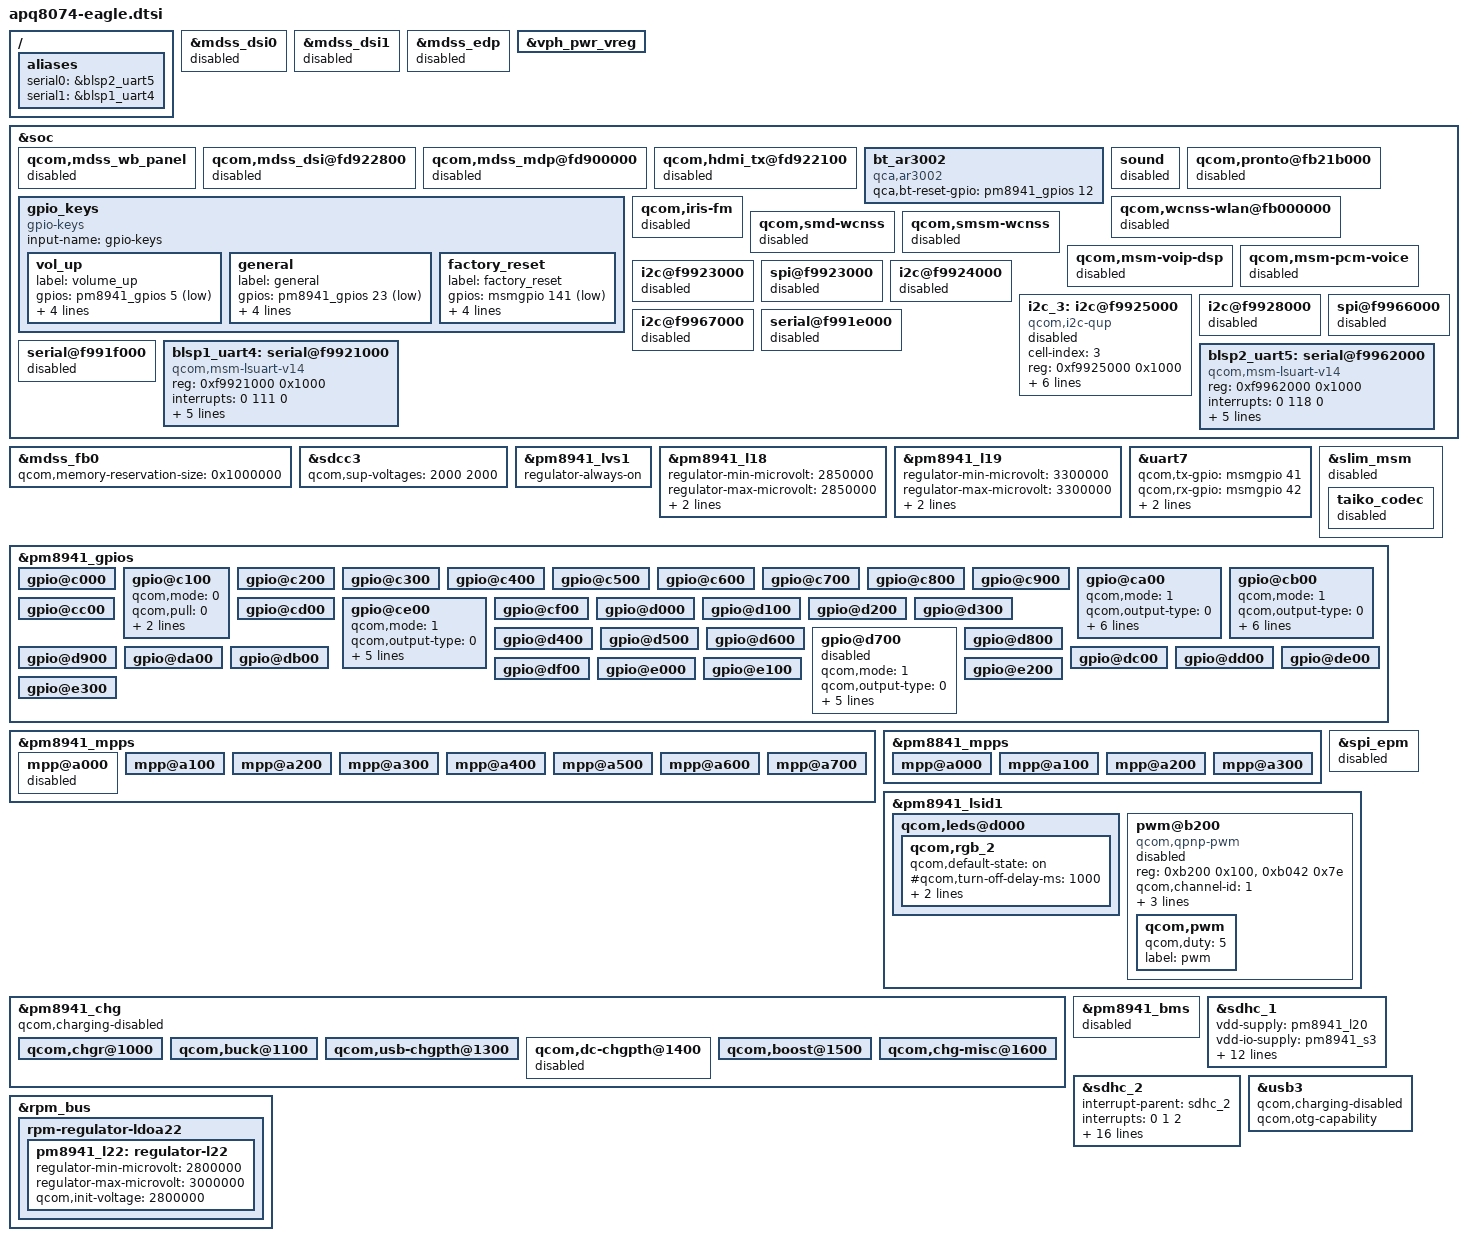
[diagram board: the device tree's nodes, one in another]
/* Copyright (c) 2013-2015, The Linux Foundation. All rights reserved.
 *
 * This program is free software; you can redistribute it and/or modify
 * it under the terms of the GNU General Public License version 2 and
 * only version 2 as published by the Free Software Foundation.
 *
 * This program is distributed in the hope that it will be useful,
 * but WITHOUT ANY WARRANTY; without even the implied warranty of
 * MERCHANTABILITY or FITNESS FOR A PARTICULAR PURPOSE.  See the
 * GNU General Public License for more details.
 */

/include/ "apq8074-camera-sensor-eagle.dtsi"
/include/ "msm8974-leds.dtsi"
/include/ "msm-rdbg.dtsi"
/include/ "apq8074-leds-eagle.dtsi"

/ {
	aliases {
		serial0 = &blsp2_uart5;
        serial1 = &blsp1_uart4;
	};
};

&mdss_dsi0 {
    status = "disabled";
};

&mdss_dsi1 {
    status = "disabled";
};

&mdss_edp {
    status = "disabled";
};

&vph_pwr_vreg {
	status = "ok";
};

&soc {

    qcom,mdss_wb_panel {
		status = "disabled";
	};

	qcom,mdss_dsi@fd922800 {
		status = "disabled";
	};

	qcom,mdss_mdp@fd900000 {
		status = "disabled";
	};

	qcom,hdmi_tx@fd922100 {
		status = "disabled";
	};

	gpio_keys {
		compatible = "gpio-keys";
		input-name = "gpio-keys";

		vol_up {
			label = "volume_up";
			gpios = <&pm8941_gpios 5 0x1>;
			linux,input-type = <1>;
			linux,code = <115>;
			gpio-key,wakeup;
			debounce-interval = <15>;
		};

		general {
			label = "general";
			gpios = <&pm8941_gpios 23 0x1>;
			linux,input-type = <1>;
			linux,code = <102>;
			gpio-key,wakeup;
			debounce-interval = <15>;
		};

		factory_reset {
			label = "factory_reset";
			gpios = <&msmgpio 141 0x1>;
			linux,input-type = <1>;
			linux,code = <766>;
			gpio-key,wakeup;
			debounce-interval = <15>;
		};
	};

	bt_ar3002 {
		compatible = "qca,ar3002";
		qca,bt-reset-gpio = <&pm8941_gpios 12 0>;
	};

	sound {
        status = "disabled";        
	};

	qcom,pronto@fb21b000 {
		status = "disabled";
	};

	qcom,iris-fm {
		status = "disabled";
	};

	qcom,wcnss-wlan@fb000000 {
		status = "disabled";
	};

	qcom,smd-wcnss {
		status = "disabled";
	};

	qcom,smsm-wcnss {
		status = "disabled";
	};

	qcom,msm-voip-dsp {
		status = "disabled";
	};

	qcom,msm-pcm-voice {
		status = "disabled";
	};


    /* blsp1 - qup i2c - na */
	i2c@f9923000 {
		status = "disabled";
	};

    /* blsp1 - qup spi - na */
	spi@f9923000 {
		status = "disabled";
	};

    /* blsp2 - qup i2c - na */
	i2c@f9924000 {
		status = "disabled";
	};

	/* blsp2 - qup i2c - barometer (keep disabled) */
	i2c_3: i2c@f9925000 {
		cell-index = <3>;
		compatible = "qcom,i2c-qup";
		reg = <0xf9925000 0x1000>;
		#address-cells = <1>;
		#size-cells = <0>;
		reg-names = "qup_phys_addr";
		interrupts = <0 97 0>;
		interrupt-names = "qup_err_intr";
		qcom,i2c-bus-freq = <384000>;
		qcom,i2c-src-freq = <19200000>;
		qcom,master-id = <86>;
		qcom,scl-gpio = <&msmgpio 11 0>;
		qcom,sda-gpio = <&msmgpio 10 0>;
		status = "disabled";
	};

    /* blsp6 - qup i2c - na */
	i2c@f9928000 {
		status = "disabled";
	};

	/* msm8974.dtsi */
    /* blsp10 - qup spi - na */
	spi@f9966000 {
		status = "disabled";
	};

	/* msm8974.dtsi */
    /* blsp11 - qup i2c - na */
	i2c@f9967000 {
		status = "disabled";
	};

	/* msm8974.dtsi */
    /* blsp2 - uart - na */
	serial@f991e000 {
		status = "disabled";
	};

	/* msm8974.dtsi */
    /* blsp3 - uart - na */
	serial@f991f000 {
		status = "disabled";
	};

	/* Not defined */
    /* blsp5 - uart - GPS */
	blsp1_uart4: serial@f9921000 {
		compatible = "qcom,msm-lsuart-v14";
		reg = <0xf9921000 0x1000>;
		interrupts = <0 111 0>;
		status = "okay";

		qcom,msm-bus,name = "serial_uart5";
		qcom,msm-bus,num-cases = <2>;
		qcom,msm-bus,num-paths = <1>;
		qcom,msm-bus,vectors-KBps =
				<86 512 0 0>,
				<86 512 500 800>;
	};

    /* blsp12 - serial console */
	blsp2_uart5: serial@f9962000 {
		compatible = "qcom,msm-lsuart-v14";
		reg = <0xf9962000 0x1000>;
		interrupts = <0 118 0>;
		status = "okay";

		qcom,msm-bus,name = "serial_uart12";
		qcom,msm-bus,num-cases = <2>;
		qcom,msm-bus,num-paths = <1>;
		qcom,msm-bus,vectors-KBps =
				<84 512 0 0>,
				<84 512 500 800>;
	};
};

&mdss_fb0 {
	qcom,memory-reservation-size = <0x1000000>; /* size 16MB */
};

&sdcc3 {
	qcom,sup-voltages = <2000 2000>;
	status = "ok";
};

&pm8941_lvs1 {
	regulator-always-on;
};

&pm8941_l18 {
    regulator-min-microvolt = <2850000>;
    regulator-max-microvolt = <2850000>;
    qcom,init-voltage = <2850000>;
	regulator-always-on;
};


&pm8941_l19 {
	regulator-min-microvolt = <3300000>;
	regulator-max-microvolt = <3300000>;
	qcom,init-voltage = <3300000>;
	regulator-always-on;
};

/* blsp7 - bt uart */
&uart7 {
	status = "ok";
	qcom,tx-gpio = <&msmgpio 41 0x00>;
	qcom,rx-gpio = <&msmgpio 42 0x00>;
	qcom,cts-gpio = <&msmgpio 43 0x00>;
	qcom,rfr-gpio = <&msmgpio 44 0x00>;
};

&slim_msm {
	status = "disabled";
	taiko_codec {
		status = "disabled";
	};
};

&pm8941_gpios {
	gpio@c000 { /* GPIO 1 */
	};

	gpio@c100 { /* GPIO 2 */
		qcom,mode = <0>;
		qcom,pull = <0>;
		qcom,vin-sel = <2>;
		qcom,src-sel = <0>;
	};

	gpio@c200 { /* GPIO 3 */
	};

	gpio@c300 { /* GPIO 4 */
	};

	gpio@c400 { /* GPIO 5 */
	};

	gpio@c500 { /* GPIO 6 */
	};

	gpio@c600 { /* GPIO 7 */
	};

	gpio@c700 { /* GPIO 8 */
	};

	gpio@c800 { /* GPIO 9 */
	};

	gpio@c900 { /* GPIO 10 */
	};

	gpio@ca00 { /* GPIO 11 - wlan_reset_n */
		qcom,mode = <1>;		/* QPNP_PIN_MODE_DIG_OUT */
		qcom,output-type = <0>;		/* QPNP_PIN_OUT_BUF_CMOS */
		qcom,pull = <5>;		/* QPNP_PIN_PULL_NO */
		qcom,vin-sel = <2>;		/* QPNP_PIN_VIN2 */
		qcom,out-strength = <2>;	/* QPNP_PIN_OUT_STRENGTH_MED */
		qcom,src-sel = <0>;		/* QPNP_PIN_SEL_FUNC_CONSTANT */
		qcom,invert = <1>;      /* active low */
		qcom,master-en = <1>;
	};

	gpio@cb00 { /* GPIO 12 - bt_reset_n */
		qcom,mode = <1>;		/* QPNP_PIN_MODE_DIG_OUT */
		qcom,output-type = <0>;		/* QPNP_PIN_OUT_BUF_CMOS */
		qcom,pull = <5>;		/* QPNP_PIN_PULL_NO */
		qcom,vin-sel = <2>;		/* QPNP_PIN_VIN2 */
		qcom,out-strength = <2>;	/* QPNP_PIN_OUT_STRENGTH_MED */
		qcom,src-sel = <0>;		/* QPNP_PIN_SEL_FUNC_CONSTANT */
		qcom,invert = <0>;
		qcom,master-en = <1>;
	};

	gpio@cc00 { /* GPIO 13 */
	};

	gpio@cd00 { /* GPIO 14 */
	};

	gpio@ce00 { /* GPIO 15 */
		qcom,mode = <1>;
		qcom,output-type = <0>;
		qcom,pull = <5>;
		qcom,vin-sel = <2>;
		qcom,out-strength = <3>;
		qcom,src-sel = <2>;
		qcom,master-en = <1>;
	};

	gpio@cf00 { /* GPIO 16 */
	};

	gpio@d000 { /* GPIO 17 */
	};

	gpio@d100 { /* GPIO 18 */
	};

	gpio@d200 { /* GPIO 19 */
	};

	gpio@d300 { /* GPIO 20 */
	};

	gpio@d400 { /* GPIO 21 */
	};

	gpio@d500 { /* GPIO 22 */
	};

	gpio@d600 { /* GPIO 23 */
	};

	gpio@d700 { /* GPIO 24 - pwm */
		status = "disabled";
		qcom,mode = <1>;		/* QPNP_PIN_MODE_DIG_OUT */
		qcom,output-type = <0>;		/* QPNP_PIN_OUT_BUF_CMOS */
		qcom,pull = <5>;		/* QPNP_PIN_PULL_NO */
		qcom,vin-sel = <2>;		/* QPNP_PIN_VIN2 */
		qcom,out-strength = <2>;	/* QPNP_PIN_OUT_STRENGTH_MED */
		qcom,src-sel = <3>;		/* QPNP_PIN_SEL_FUNC_2 */
		qcom,master-en = <1>;
	};

	gpio@d800 { /* GPIO 25 */
	};

	gpio@d900 { /* GPIO 26 */
	};

	gpio@da00 { /* GPIO 27 */
	};

	gpio@db00 { /* GPIO 28 */
	};

	gpio@dc00 { /* GPIO 29 */
	};

	gpio@dd00 { /* GPIO 30 */
	};

	gpio@de00 { /* GPIO 31 */
	};

	gpio@df00 { /* GPIO 32 */
	};

	gpio@e000 { /* GPIO 33 */
	};

	gpio@e100 { /* GPIO 34 */
	};

	gpio@e200 { /* GPIO 35 */
	};

	gpio@e300 { /* GPIO 36 */
	};
};

&pm8941_mpps {

	mpp@a000 { /* MPP 1 */
		status = "disabled";
	};

	mpp@a100 { /* MPP 2 */
	};

	mpp@a200 { /* MPP 3 */
	};

	mpp@a300 { /* MPP 4 */
	};

	mpp@a400 { /* MPP 5 */
	};

	mpp@a500 { /* MPP 6 */
	};

	mpp@a600 { /* MPP 7 */
	};

	mpp@a700 { /* MPP 8 */
	};
};

&pm8841_mpps {

	mpp@a000 { /* MPP 1 */
	};

	mpp@a100 { /* MPP 2 */
	};

	mpp@a200 { /* MPP 3*/
	};

	mpp@a300 { /* MPP 4*/
	};
};

&spi_epm {
	status = "disabled";
};

&pm8941_lsid1 {

    qcom,leds@d000 {
        qcom,rgb_2 {
            status = "ok";
            qcom,default-state = "on";
			#qcom,turn-off-delay-ms = <1000>;
            qcom,idx-len = <1>;
            qcom,duty-pcts = [40];
        };
		/*
        qcom,rgb_1 {
            status = "ok";
            qcom,default-state = "on";
            qcom,idx-len = <1>;
            qcom,duty-pcts = [40];
        };*/
    };

	/* channel 1 */
	pwm@b200 {
		status = "disabled";
		compatible = "qcom,qpnp-pwm";
		reg = <0xb200 0x100>,
		      <0xb042 0x7e>;
		reg-names = "qpnp-lpg-channel-base", "qpnp-lpg-lut-base";
		qcom,channel-id = <1>;

        /* override */
		qcom,mode-select = <0>; /* pwm */
		qcom,period = <10>; /* 10 microseconds */
		qcom,force-pwm-size = <9>;
		qcom,pwm {
			qcom,duty = <5>; /* 5 microseconds */
			label = "pwm";
		};
	};
};

&pm8941_chg {
	status = "ok";

	qcom,charging-disabled;

	qcom,chgr@1000 {
		status = "ok";
	};

	qcom,buck@1100 {
		status = "ok";
	};

	qcom,usb-chgpth@1300 {
		status = "ok";
	};

	qcom,dc-chgpth@1400 {
		status = "disabled";
	};

	qcom,boost@1500 {
		status = "ok";
	};

	qcom,chg-misc@1600 {
		status = "ok";
	};
};

&pm8941_bms {
	status = "disabled";
};

&sdhc_1 {
	vdd-supply = <&pm8941_l20>;
	vdd-io-supply = <&pm8941_s3>;

	qcom,vdd-always-on;
	qcom,vdd-lpm-sup;
	qcom,vdd-voltage-level = <2950000 2950000>;
	qcom,vdd-current-level = <800 500000>;

	qcom,vdd-io-always-on;
	qcom,vdd-io-voltage-level = <1800000 1800000>;
	qcom,vdd-io-current-level = <250 154000>;

	qcom,pad-pull-on = <0x0 0x3 0x3>; /* no-pull, pull-up, pull-up */
	qcom,pad-pull-off = <0x0 0x3 0x3>; /* no-pull, pull-up, pull-up */
	qcom,pad-drv-on = <0x4 0x4 0x4>; /* 10mA, 10mA, 10mA */
	qcom,pad-drv-off = <0x0 0x0 0x0>; /* 2mA, 2mA, 2mA */

	qcom,nonremovable;
	status = "ok";
};

&sdhc_2 {
	#address-cells = <0>;
	interrupt-parent = <&sdhc_2>;
	interrupts = <0 1 2>;
	#interrupt-cells = <1>;
	interrupt-map-mask = <0xffffffff>;
	interrupt-map = <0 &intc 0 125 0
			1 &intc 0 221 0
			2 &msmgpio 62 0x3>;
	interrupt-names = "hc_irq", "pwr_irq", "status_irq";
	cd-gpios = <&msmgpio 62 0x1>;

	qcom,vdd-always-on;
	qcom,vdd-lpm-sup;

	vdd-supply = <&pm8941_l21>;
	vdd-io-supply = <&pm8941_l13>;

	qcom,vdd-voltage-level = <2950000 2950000>;
	qcom,vdd-current-level = <9000 800000>;

	qcom,vdd-io-voltage-level = <1800000 2950000>;
	qcom,vdd-io-current-level = <6 22000>;

	qcom,pad-pull-on = <0x0 0x3 0x3>; /* no-pull, pull-up, pull-up */
	qcom,pad-pull-off = <0x0 0x3 0x3>; /* no-pull, pull-up, pull-up */
	qcom,pad-drv-on = <0x4 0x4 0x4>; /* 10mA, 10mA, 10mA */
	qcom,pad-drv-off = <0x0 0x0 0x0>; /* 2mA, 2mA, 2mA */
	status = "ok";
};

&usb3 {
	qcom,charging-disabled;
	qcom,otg-capability;
};

&rpm_bus { 

	rpm-regulator-ldoa22 {  /* Regulator setting for ov7251 sensor on eagle*/
 		status = "okay";
 		pm8941_l22: regulator-l22 {
			regulator-min-microvolt = <2800000>;
 			regulator-max-microvolt = <3000000>;
			qcom,init-voltage = <2800000>;
 			status = "okay";
 		};
 	};

};
